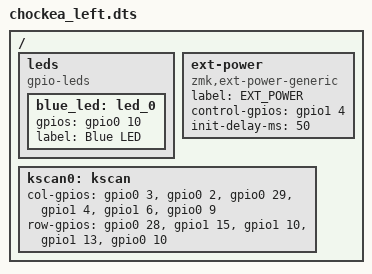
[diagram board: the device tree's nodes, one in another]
/*
 * Copyright (c) 2021 Thys de Wet (vattern)
 *
 * SPDX-License-Identifier: MIT
 */

/dts-v1/;
#include <nordic/nrf52840_qiaa.dtsi>
#include <dt-bindings/zmk/matrix_transform.h>
#include "chockea.dtsi"
/ {

leds {
  compatible = "gpio-leds";
  blue_led: led_0 {
    gpios = <&gpio0 10 GPIO_ACTIVE_HIGH>;
    label = "Blue LED";
  };
};
ext-power {
    compatible = "zmk,ext-power-generic";
    label = "EXT_POWER";
    control-gpios = <&gpio1 4 GPIO_ACTIVE_HIGH>;
    init-delay-ms = <50>;
  };
  
kscan0: kscan {
    col-gpios
        = <&gpio0 3  (GPIO_ACTIVE_HIGH | GPIO_PULL_DOWN)>
        , <&gpio0 2  (GPIO_ACTIVE_HIGH | GPIO_PULL_DOWN)>
        , <&gpio0 29 (GPIO_ACTIVE_HIGH | GPIO_PULL_DOWN)>
        , <&gpio1 4  (GPIO_ACTIVE_HIGH | GPIO_PULL_DOWN)>
        , <&gpio1 6  (GPIO_ACTIVE_HIGH | GPIO_PULL_DOWN)>
        , <&gpio0 9  (GPIO_ACTIVE_HIGH | GPIO_PULL_DOWN)>
        ;
    row-gpios
        = <&gpio0 28 (GPIO_ACTIVE_HIGH )>
        , <&gpio1 15  (GPIO_ACTIVE_HIGH )>
        , <&gpio1 10 (GPIO_ACTIVE_HIGH )>
        , <&gpio1 13  (GPIO_ACTIVE_HIGH )>
        , <&gpio0 10  (GPIO_ACTIVE_HIGH )>
        ;
        };
    };
